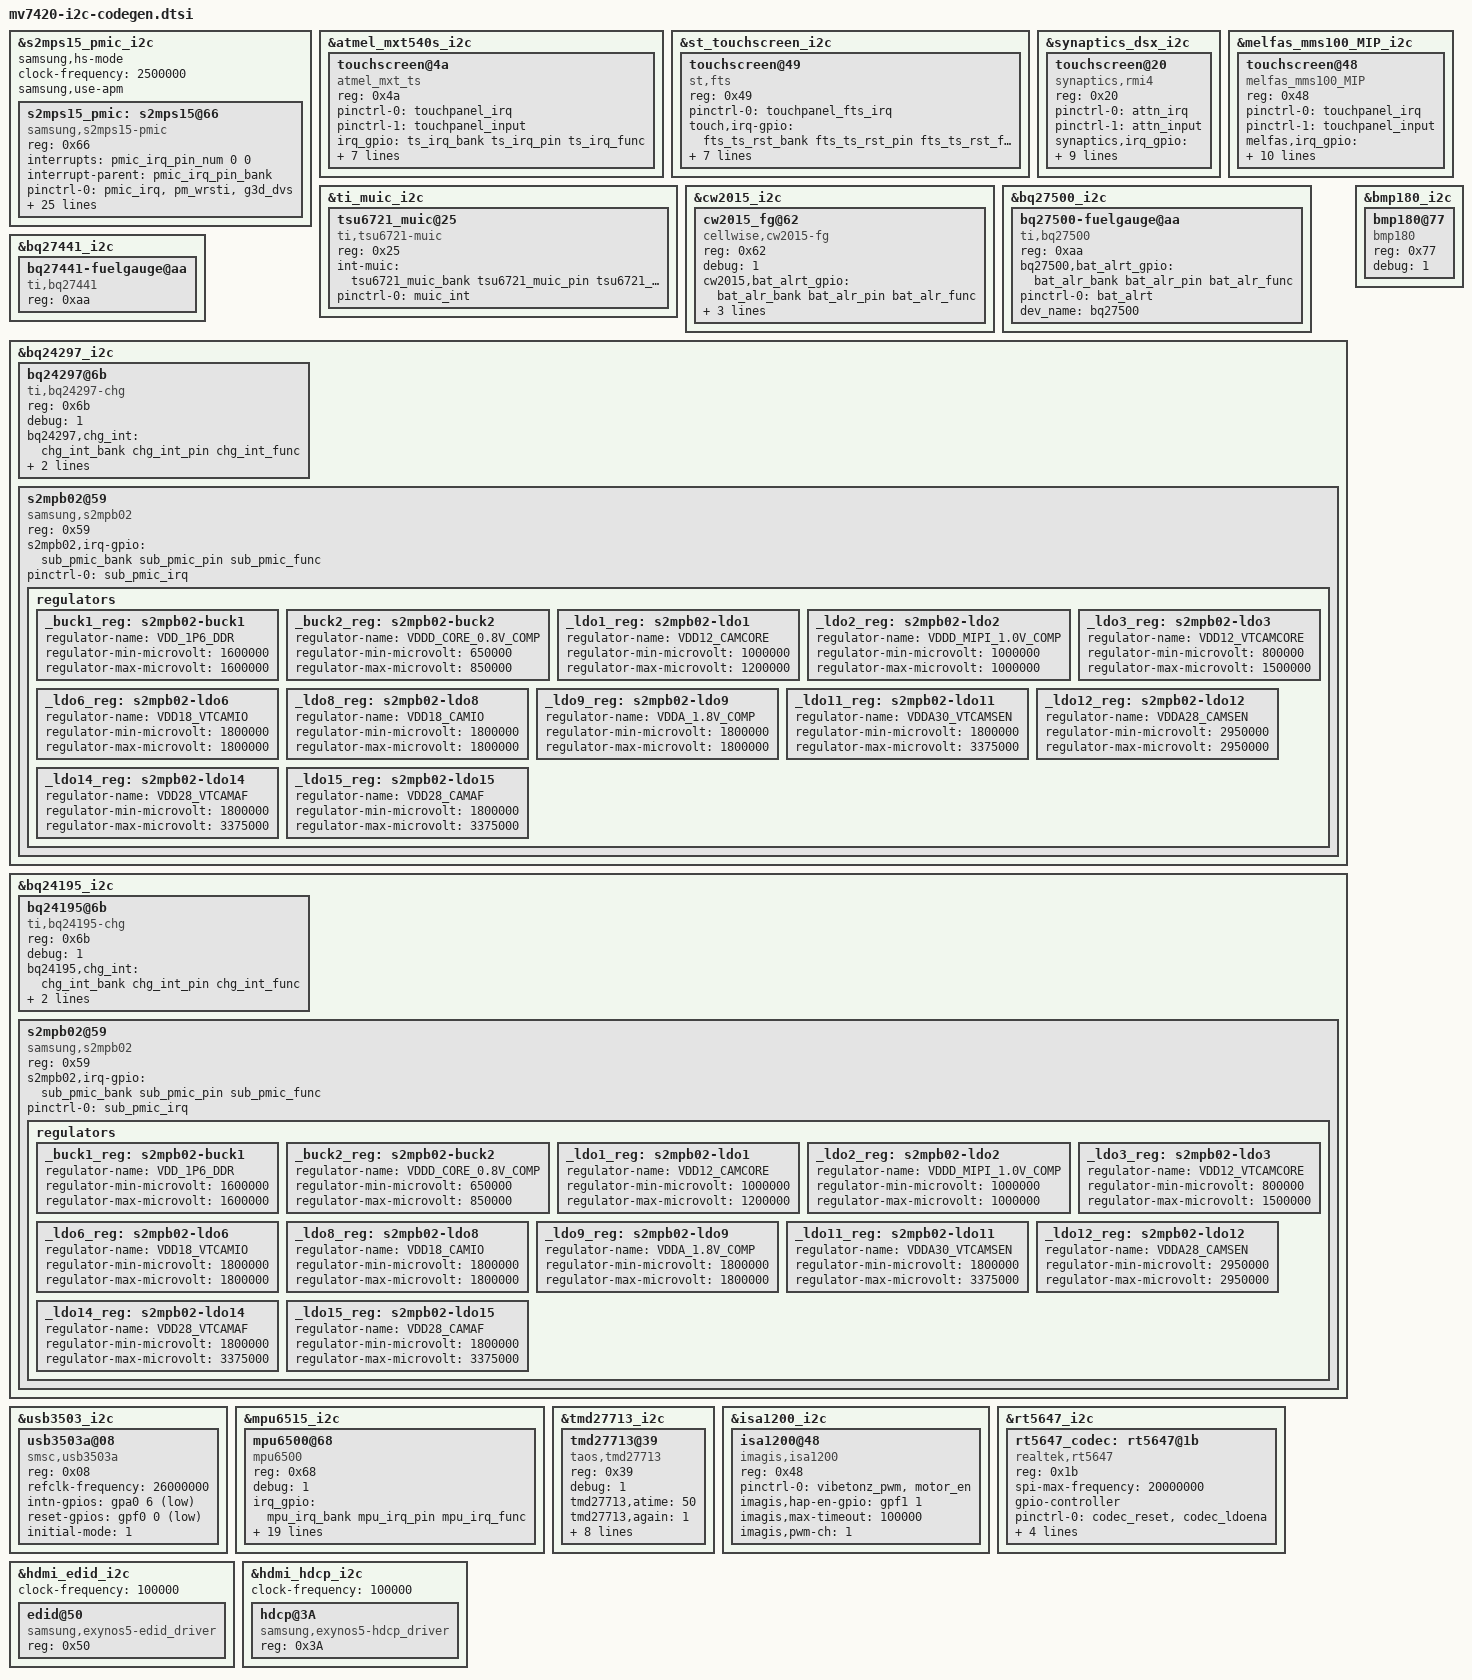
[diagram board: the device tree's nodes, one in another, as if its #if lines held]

#include "mv7420-i2c-codegen.h"
#include "mv7420-gpio-codegen.h"
#include "mv7420-pinctrl-codegen.h"

&s2mps15_pmic_i2c {
		status = "okay";
		samsung,hs-mode;
		clock-frequency = <2500000>;
		samsung,use-apm;

		s2mps15_pmic: s2mps15@66 {
			compatible = "samsung,s2mps15-pmic";
			reg = <0x66>;
			interrupts = <pmic_irq_pin_num 0 0>;
			interrupt-parent = <&pmic_irq_pin_bank>;
			pinctrl-names = "default";
			pinctrl-0 = <&pmic_irq &pm_wrsti &g3d_dvs>;
			gpios = <&pmic_gpio0_bank pmic_gpio0_pin pmic_gpio0_func>, 
					<&pmic_gpio1_bank pmic_gpio1_pin pmic_gpio1_func>, 
						<&pmic_gpio2_bank pmic_gpio2_pin pmic_gpio2_func>;
			smpl_warn_en = <1>; /* 1 : enable , 0 : disable*/
			/* range of smpl_warn_vth */
			/* PMIC1 */
			/* 2100 : 2.3V, 2300 : 2.3V, 2500 : 2.5V, 2700 : 2.7V 2900 : 2.9V */
			/* 3100 : 3.0V, 3300 : 3.0V, 3500 : 3.0V */
			/* PMIC2 */
			/* 2100 : 2.1V, 2300 : 2.3V, 2500 : 2.5V, 2700 : 2.7V 2900 : 2.9V */
			/* 3100 : 3.1V, 3300 : 3.3V, 3500 : 3.5V */
			smpl_warn_vth = <2900>;
			smpl_warn_hys = <0x00>; /* LOwBat_Hys[4:3] 00(100mV)~11(400mV) */
			adc-on;
			buck_dvs_on;
			g3d_en = <1>; /* 1 : enable , 0 : disable */
			dvs_en = <1>; /* 1 : enable , 0 : disable */
			buck6en_pin = "pmic_buck6en_gpio";
			buck6en_addr = "13470000.pinctrl";
			/* RTC: wtsr/smpl */
			wtsr_en = <1>; /* enable */
			smpl_en = <1>; /* enable */
			wtsr_timer_val = <3>;	/* 1000ms */
			smpl_timer_val = <4>;	/* 500ms */
			check_jigon = <0>; /* do not check jigon */
			/* RTC: If it's first boot, reset rtc to 1/1/2014 12:00:00(Wed) */
			init_time,sec = <0>;
			init_time,min = <0>;
			init_time,hour = <12>;
			init_time,mday = <1>;
			init_time,mon = <0>;
			init_time,year = <114>;
			init_time,wday = <3>;
		};
};

#ifdef CONFIG_DTS_TOUCHSCREEN_ATMEL_MXTS
&atmel_mxt540s_i2c {
		status = "okay";
		touchscreen@4a {
			compatible = "atmel_mxt_ts";
			reg = <0x4a>;
			pinctrl-names = "on_state", "off_state";
			pinctrl-0 = <&touchpanel_irq>;
			pinctrl-1 = <&touchpanel_input>;
			irq_gpio = <&ts_irq_bank ts_irq_pin ts_irq_func>;
			irq_type = <8200>;
			reset_gpio = <&ts_rst_bank ts_rst_pin ts_rst_func>;
			t15_num_keys = <0>;
			regulator_vddio = "tsp_18v";
			regulator_vdd = "tsp_28v";
			tsp_18v-supply = <&atmel_mxt540s_supply18>;
			tsp_28v-supply = <&atmel_mxt540s_supply28>;
		};
};
#endif

#ifdef CONFIG_DTS_TOUCHSCREEN_FTS
&st_touchscreen_i2c {
		status = "okay";
		touchscreen@49 {
			compatible = "st,fts";
			reg = <0x49>;
			/*pinctrl-names = "on_state", "off_state";*/
			pinctrl-names = "touch_irq";
			pinctrl-0 = <&touchpanel_fts_irq>;
			/*pinctrl-1 = <&touchpanel_input>;*/
			touch,irq-gpio = <&fts_ts_rst_bank fts_ts_rst_pin fts_ts_rst_func>;
			irq_type = <8200>;
			touch,reset-gpio = <&ts_rst_bank ts_rst_pin ts_rst_func>;
			touch,regulator_vddio = "tsp_18v";
			touch,regulator_vdd = "tsp_28v";
			tsp_18v-supply = <&touchscreen_fts_supply18>;
			tsp_28v-supply = <&touchscreen_fts_supply33>;
		};
};
#endif

#ifdef CONFIG_DTS_TOUCHSCREEN_SYNAPTICS_DSX
&synaptics_dsx_i2c {
		status = "okay";
		touchscreen@20 {
			compatible = "synaptics,rmi4";
			reg = <0x20>;
			pinctrl-names = "on_state", "off_state";
			pinctrl-0 = <&attn_irq>;
			pinctrl-1 = <&attn_input>;
			synaptics,irq_gpio = <&ts_irq_bank ts_irq_pin ts_irq_func>;
			synaptics,irq_type = <8200>;
			synaptics,max_coords = <1080 1920>;     /* x y */
			synaptics,num_lines = <29 16>;          /* rx tx */
			synaptics,regulator_dvdd = "vdd_ldo23"; /* ldo23*/
			synaptics,regulator_avdd = "vdd_ldo19"; /* ldo19*/
			synaptics,project_name = "mv7420-lcd", "mv7420";
			synaptics,panel_revision =<1>;
			synaptics,device_num = <1>;
		};		
};
#endif

#ifdef CONFIG_DTS_TOUCHSCREEN_MELFAS
&melfas_mms100_MIP_i2c {
		status = "okay";
		touchscreen@48 {
			compatible = "melfas_mms100_MIP";
			reg = <0x48>;
			pinctrl-names = "on_state", "off_state";
			pinctrl-0 = <&touchpanel_irq>;
			pinctrl-1 = <&touchpanel_input>;
			melfas,irq_gpio = <&ts_irq_bank ts_irq_pin ts_irq_func>;
			melfas,irq_type = <8200>;
			melfas,reset_gpio = <&ts_rst_bank ts_rst_pin ts_rst_func>;
			melfas,max_coords = <720 1280>;
			melfas,num_lines = <255 30>;
			melfas,regulator_dvdd = "tsp_18v";
			melfas,regulator_avdd = "tsp_28v";
			tsp_18v-supply = <&melfas_supply18>;
			tsp_28v-supply = <&melfas_supply28>;
		};
};
#endif

#ifdef CONFIG_DTS_TSU6721_MUIC
&ti_muic_i2c{
	status = "okay";

	tsu6721_muic@25{
		compatible = "ti,tsu6721-muic";
		reg = <0x25>;
		int-muic = <&tsu6721_muic_bank tsu6721_muic_pin tsu6721_muic_func>;
		pinctrl-names = "default";
		pinctrl-0 = <&muic_int>;
	};
};
#endif

#ifdef CONFIG_DTS_BATTERY_CW2015
&cw2015_i2c {
		status = "okay";
		cw2015_fg@62 {
			compatible = "cellwise,cw2015-fg";
			reg = <0x62>;
			debug = <1>;
			cw2015,bat_alrt_gpio = <&bat_alr_bank bat_alr_pin bat_alr_func>;
			pinctrl-names = "default";
			pinctrl-0 = <&bat_alrt>;
			bat_conf_info = [
				//* PL-6G 1600mAh
				17 52 72 6F 6D 66 63 60
				5E 58 58 54 56 4E 44 34
				2E 24 1E 17 21 31 3B 49
				31 41 0C CD 09 12 29 3B
				44 46 46 47 3E 1A 52 18
				0B 44 52 87 8F 91 94 52
				82 8C 92 96 60 77 D0 CB
				2F 7D 72 A5 B5 C1 8D 09
				//*/
			];
		};
};
#endif

#ifdef CONFIG_DTS_BATTERY_BQ27425
&bq27500_i2c {
		status = "okay";
		bq27500-fuelgauge@aa {
		    compatible = "ti,bq27500";
		    reg = <0xaa>;
		    bq27500,bat_alrt_gpio = <&bat_alr_bank bat_alr_pin bat_alr_func>;
		    pinctrl-names = "default";
		    pinctrl-0 = <&bat_alrt>;
		    dev_name = "bq27500";
		};
};
#endif

#ifdef CONFIG_DTS_BATTERY_BQ27441
&bq27441_i2c {
		status = "okay";
		bq27441-fuelgauge@aa {
		    compatible = "ti,bq27441";
		    reg = <0xaa>;
		};
};
#endif

#ifdef CONFIG_DTS_CHARGER_BQ24297
&bq24297_i2c {
		status = "okay";
		bq24297@6b {
			compatible = "ti,bq24297-chg";
			reg = <0x6b>;
			debug = <1>;
			bq24297,chg_int = <&chg_int_bank chg_int_pin chg_int_func>;
			pinctrl-names = "default";
			pinctrl-0 = <&chg_irq>;
			bq24297,vmax = <4200>;
		};
	
		s2mpb02@59 {
			compatible = "samsung,s2mpb02";
			reg = <0x59>;
			s2mpb02,irq-gpio=<&sub_pmic_bank sub_pmic_pin  sub_pmic_func>;
			pinctrl-names = "default";
			pinctrl-0 = <&sub_pmic_irq>;
			regulators {
				_buck1_reg: s2mpb02-buck1 {
					regulator-name = "VDD_1P6_DDR";
					regulator-min-microvolt = <1600000>;
					regulator-max-microvolt = <1600000>;
				};

				_buck2_reg: s2mpb02-buck2 {
					regulator-name = "VDDD_CORE_0.8V_COMP";
					regulator-min-microvolt = <650000>;
					regulator-max-microvolt = <850000>;
				};

				_ldo1_reg: s2mpb02-ldo1 {
					regulator-name = "VDD12_CAMCORE";
					regulator-min-microvolt = <1000000>;
					regulator-max-microvolt = <1200000>;
				};

				_ldo2_reg: s2mpb02-ldo2 {
					regulator-name = "VDDD_MIPI_1.0V_COMP";
					regulator-min-microvolt = <1000000>;
					regulator-max-microvolt = <1000000>;
				};

				_ldo3_reg: s2mpb02-ldo3 {
					regulator-name = "VDD12_VTCAMCORE";
					regulator-min-microvolt = <800000>;
					regulator-max-microvolt = <1500000>;
				};

				_ldo6_reg: s2mpb02-ldo6 {
					regulator-name = "VDD18_VTCAMIO";
					regulator-min-microvolt = <1800000>;
					regulator-max-microvolt = <1800000>;
				};

				_ldo8_reg: s2mpb02-ldo8 {
					regulator-name = "VDD18_CAMIO";
					regulator-min-microvolt = <1800000>;
					regulator-max-microvolt = <1800000>;
				};

				_ldo9_reg: s2mpb02-ldo9 {
					regulator-name = "VDDA_1.8V_COMP";
					regulator-min-microvolt = <1800000>;
					regulator-max-microvolt = <1800000>;
				};

				_ldo11_reg: s2mpb02-ldo11 {
					regulator-name = "VDDA30_VTCAMSEN";
					regulator-min-microvolt = <1800000>;
					regulator-max-microvolt = <3375000>;
				};

				_ldo12_reg: s2mpb02-ldo12 {
					regulator-name = "VDDA28_CAMSEN";
					regulator-min-microvolt = <2950000>;
					regulator-max-microvolt = <2950000>;
				};

				_ldo14_reg: s2mpb02-ldo14 {
					regulator-name = "VDD28_VTCAMAF";
					regulator-min-microvolt = <1800000>;
					regulator-max-microvolt = <3375000>;
				};

				_ldo15_reg: s2mpb02-ldo15 {
					regulator-name = "VDD28_CAMAF";
					regulator-min-microvolt = <1800000>;
					regulator-max-microvolt = <3375000>;
				};

			};
	};

};
#endif


#ifdef CONFIG_DTS_CHARGER_BQ24195
&bq24195_i2c {
		status = "okay";
		bq24195@6b {
			compatible = "ti,bq24195-chg";
			reg = <0x6b>;
			debug = <1>;
			bq24195,chg_int = <&chg_int_bank chg_int_pin chg_int_func>;
			pinctrl-names = "default";
			pinctrl-0 = <&chg_irq>;
			bq24195,vmax = <4200>;
		};
		
		s2mpb02@59 {
			compatible = "samsung,s2mpb02";
			reg = <0x59>;
			s2mpb02,irq-gpio=<&sub_pmic_bank sub_pmic_pin  sub_pmic_func>;
			pinctrl-names = "default";
			pinctrl-0 = <&sub_pmic_irq>;
			regulators {
				_buck1_reg: s2mpb02-buck1 {
					regulator-name = "VDD_1P6_DDR";
					regulator-min-microvolt = <1600000>;
					regulator-max-microvolt = <1600000>;
				};

				_buck2_reg: s2mpb02-buck2 {
					regulator-name = "VDDD_CORE_0.8V_COMP";
					regulator-min-microvolt = <650000>;
					regulator-max-microvolt = <850000>;
				};

				_ldo1_reg: s2mpb02-ldo1 {
					regulator-name = "VDD12_CAMCORE";
					regulator-min-microvolt = <1000000>;
					regulator-max-microvolt = <1200000>;
				};

				_ldo2_reg: s2mpb02-ldo2 {
					regulator-name = "VDDD_MIPI_1.0V_COMP";
					regulator-min-microvolt = <1000000>;
					regulator-max-microvolt = <1000000>;
				};

				_ldo3_reg: s2mpb02-ldo3 {
					regulator-name = "VDD12_VTCAMCORE";
					regulator-min-microvolt = <800000>;
					regulator-max-microvolt = <1500000>;
				};

				_ldo6_reg: s2mpb02-ldo6 {
					regulator-name = "VDD18_VTCAMIO";
					regulator-min-microvolt = <1800000>;
					regulator-max-microvolt = <1800000>;
				};

				_ldo8_reg: s2mpb02-ldo8 {
					regulator-name = "VDD18_CAMIO";
					regulator-min-microvolt = <1800000>;
					regulator-max-microvolt = <1800000>;
				};

				_ldo9_reg: s2mpb02-ldo9 {
					regulator-name = "VDDA_1.8V_COMP";
					regulator-min-microvolt = <1800000>;
					regulator-max-microvolt = <1800000>;
				};

				_ldo11_reg: s2mpb02-ldo11 {
					regulator-name = "VDDA30_VTCAMSEN";
					regulator-min-microvolt = <1800000>;
					regulator-max-microvolt = <3375000>;
				};

				_ldo12_reg: s2mpb02-ldo12 {
					regulator-name = "VDDA28_CAMSEN";
					regulator-min-microvolt = <2950000>;
					regulator-max-microvolt = <2950000>;
				};

				_ldo14_reg: s2mpb02-ldo14 {
					regulator-name = "VDD28_VTCAMAF";
					regulator-min-microvolt = <1800000>;
					regulator-max-microvolt = <3375000>;
				};

				_ldo15_reg: s2mpb02-ldo15 {
					regulator-name = "VDD28_CAMAF";
					regulator-min-microvolt = <1800000>;
					regulator-max-microvolt = <3375000>;
				};

			};


		};
};
#endif
&usb3503_i2c{
	status ="okay";
	usb3503a@08 {
		compatible = "smsc,usb3503a";
		reg = <0x08>;
		refclk-frequency=<26000000>;
		intn-gpios = <&gpa0 6 1>;
		reset-gpios = <&gpf0 0 1>;
		pinctrl-names = "default";
		initial-mode = <1>;
	};
};

#ifdef CONFIG_DTS_SENSOR_MPU6500
&mpu6515_i2c {
	status = "okay";
	mpu6500@68 {
		compatible = "mpu6500";
		reg = <0x68>;
		debug = <1>;
		irq_gpio = <&mpu_irq_bank mpu_irq_pin mpu_irq_func>;
		pinctrl-names = "default";
		pinctrl-0 = <&gyro_irq>;

		/* TODO: need to calibrate */
		axis_map_x = <1>;
		negate_x = <0>;
		axis_map_y = <0>;
		negate_y = <0>;
		axis_map_z = <2>;
		negate_z = <0>;

		inven,secondary_type = "compass";
		inven,secondary_name = "ak8963";
		inven,secondary_reg = <0x0c>;

		/* TODO: need to calibrate */
		inven,secondary_axis_map_x = <0>;
		inven,secondary_negate_x = <1>;
		inven,secondary_axis_map_y = <1>;
		inven,secondary_negate_y = <1>;
		inven,secondary_axis_map_z = <2>;
		inven,secondary_negate_z = <0>;

		inven,aux_type = "none";

		inven,vdd_ana-supply = <&sensor_supply28>;
		inven,vcc_i2c-supply = <&sensor_supply18>;
	};
};
#endif

#ifdef CONFIG_DTS_SENSOR_BMP180
&bmp180_i2c {
	status = "okay";

	bmp180@77 {
		compatible = "bmp180";
		reg = <0x77>;
		debug = <1>;
	};
};
#endif

#ifdef CONFIG_DTS_SENSOR_TMD2771X
&tmd27713_i2c {
		status = "okay";

		tmd27713@39 {
			compatible = "taos,tmd27713";
			reg = <0x39>;
			debug = <1>;
			/* In order to reject 50/60Hz ripple strongly present in fluorescent lighting,
			 * 50ms or multiples of 50ms are recommended.
			 */
			tmd27713,atime = <50>;// 50ms
			tmd27713,again = <1>;// 1x
			tmd27713,apers = <1>;// 1 value out of range -> 1 interrupt
			tmd27713,ppers = <2>;// 1 value out of range -> 1 interrupt
			tmd27713,ptime = <2>;
			tmd27713,pdiode = <2>;
			tmd27713,wtime = <2>;
			tmd27713,lp_int = <&tmd_lp_int_bank tmd_lp_int_pin tmd_lp_int_func>;
			pinctrl-names = "default";
			pinctrl-0 = <&lp_irq>;
		};
};
#endif

&isa1200_i2c {
		status = "okay";
		isa1200@48 {
			reg = <0x48>;
			compatible = "imagis,isa1200";
			pinctrl-names = "default";
			pinctrl-0 = <&vibetonz_pwm &motor_en>;
			imagis,hap-en-gpio = <&gpf1 1 0>;
			imagis,max-timeout = <100000>;
			imagis,pwm-ch = <1>;
		};
};

/*
   vibrator {
  		compatible = "samsung,exynos7420-vib";
   		pinctrl-names = "default";
   		pinctrl-0 = <&vibetonz_pwm>;
   		samsung,pwm-ch = <1>;
   		samsung,max-timeout = <100000>;
   };
 */





#ifdef CONFIG_DTS_AUDIOCODEC_RT5647
&rt5647_i2c {
		status = "okay";
		rt5647_codec: rt5647@1b {
			 compatible = "realtek,rt5647";
			 reg = <0x1b>;
			 spi-max-frequency = <20000000>;
			 gpio-controller;
			 pinctrl-names ="default";
			 pinctrl-0 = <&codec_reset &codec_ldoena>;
			 realtek,reset = <&audio_rt5647_rst_bank audio_rt5647_rst_pin audio_rt5647_rst_func>;
			 realtek,ldoena = <&audio_rt5647_ldoena_bank audio_rt5647_ldoena_pin audio_rt5647_ldoena_func>;
			      };
};
#endif

#ifdef CONFIG_DTS_HDMI_EDID
&hdmi_edid_i2c {
		status = "okay";
		clock-frequency = <100000>;
		/* hdmi edid dirver */
		edid@50 {
			compatible = "samsung,exynos5-edid_driver";
			reg = <0x50>;
		};
};
#endif

#ifdef CONFIG_DTS_HDMI_HDCP
&hdmi_hdcp_i2c {
		status = "okay";
		clock-frequency = <100000>;
		/* hdmi hdcp dirver */
		hdcp@3A {
			compatible = "samsung,exynos5-hdcp_driver";
			reg = <0x3A>;
		};
};
#endif
#if 0
&fimc_is_sensor_i2c {
		gpios = <&fimc_6b2_i2c_sda_bank fimc_6b2_i2c_sda_pin fimc_6b2_i2c_sda_func 
				&fimc_6b2_i2c_scl_bank fimc_6b2_i2c_scl_pin fimc_6b2_i2c_scl_func >;
		samsung,i2c-sda-delay = <100>;
		samsung,i2c-max-bus-freq = <400000>;
		status = "okay";
		fimc-is-vision@20 {
			compatible = "samsung,exynos5-fimc-is-sensor-6b2";
			reg = <0x10>;
		};
};
#endif
